# LAN9255ZMX018 register map
Vendor: Microchip
Registers are 32-bit, read-write, reset 0x0 unless marked. A register's access mark holds for its fields unless they carry their own. Addresses are absolute, and some are shared; only a register's first bit layout is shown; [hi:lo] are bit positions; {n}, {i} and the like mark numbered series; 'fields as' and 'values as' point back to an identical list.

## PORT
0x41008000 GROUP0DIR
  [31:0] DIR — Port Data Direction
0x41008004 GROUP0DIRCLR
  [31:0] DIRCLR — Port Data Direction Clear
0x41008008 GROUP0DIRSET
  [31:0] DIRSET — Port Data Direction Set
0x4100800C GROUP0DIRTGL
  [31:0] DIRTGL — Port Data Direction Toggle
0x41008010 GROUP0OUT
  [31:0] OUT — PORT Data Output Value
0x41008014 GROUP0OUTCLR
  [31:0] OUTCLR — PORT Data Output Value Clear
0x41008018 GROUP0OUTSET
  [31:0] OUTSET — PORT Data Output Value Set
0x4100801C GROUP0OUTTGL
  [31:0] OUTTGL — PORT Data Output Value Toggle
0x41008020 GROUP0IN ro
  [31:0] IN — PORT Data Input Value
0x41008024 GROUP0CTRL
  [31:0] SAMPLING — Input Sampling Mode
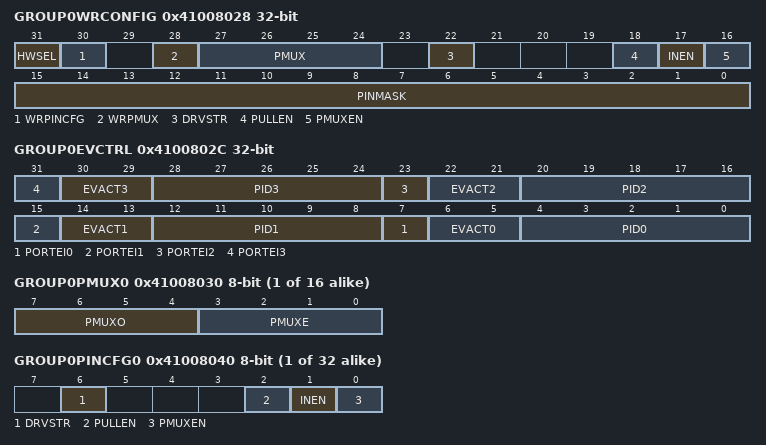
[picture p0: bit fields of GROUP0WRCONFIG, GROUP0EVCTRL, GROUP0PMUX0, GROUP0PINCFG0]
0x41008028 GROUP0WRCONFIG wo
  [31] HWSEL — Half-Word Select
  [30] WRPINCFG — Write PINCFG
  [28] WRPMUX — Write PMUX
  [27:24] PMUX — Peripheral Multiplexing
  [22] DRVSTR — Output Driver Strength Selection
  [18] PULLEN — Pull Enable
  [17] INEN — Input Enable
  [16] PMUXEN — Peripheral Multiplexer Enable
  [15:0] PINMASK — Pin Mask for Multiple Pin Configuration
0x4100802C GROUP0EVCTRL
  [8n+7] PORTEI{n} (n=0..3) — PORT Event Input Enable {n}
  [30:29] EVACT3 — PORT Event Action 3
  [8n+4:8n] PID{n} (n=0..3) — PORT Event Pin Identifier {n}
  [22:21] EVACT2 — PORT Event Action 2
  [14:13] EVACT1 — PORT Event Action 1
  [6:5] EVACT0 — PORT Event Action 0
    0=OUT (Event output to pin); 1=SET (Set output register of pin on event); 2=CLR (Clear output register of pin on event); 3=TGL (Toggle output register of pin on event)
{0x41008030+i} GROUP0PMUX{i} 8-bit (i=0..15)
  [7:4] PMUXO — Peripheral Multiplexing for Odd-Numbered Pin
    0=A (Peripheral function A selected); 1=B (Peripheral function B selected); 2=C (Peripheral function C selected); 3=D (Peripheral function D selected); 4=E (Peripheral function E selected); 5=F (Peripheral function F selected); 6=G (Peripheral function G selected); 7=H (Peripheral function H selected); 8=I (Peripheral function I selected); 9=J (Peripheral function J selected); 10=K (Peripheral function K selected); 11=L (Peripheral function L selected); 12=M (Peripheral function M selected); 13=N (Peripheral function N selected)
  [3:0] PMUXE — Peripheral Multiplexing for Even-Numbered Pin
    values as PMUXO
{0x41008040+i} GROUP0PINCFG{i} 8-bit (i=0..31)
  [6] DRVSTR — Output Driver Strength Selection
  [2] PULLEN — Pull Enable
  [1] INEN — Input Enable
  [0] PMUXEN — Peripheral Multiplexer Enable
0x41008080 GROUP1DIR
  [31:0] DIR — Port Data Direction
0x41008084 GROUP1DIRCLR
  [31:0] DIRCLR — Port Data Direction Clear
0x41008088 GROUP1DIRSET
  [31:0] DIRSET — Port Data Direction Set
0x4100808C GROUP1DIRTGL
  [31:0] DIRTGL — Port Data Direction Toggle
0x41008090 GROUP1OUT
  [31:0] OUT — PORT Data Output Value
0x41008094 GROUP1OUTCLR
  [31:0] OUTCLR — PORT Data Output Value Clear
0x41008098 GROUP1OUTSET
  [31:0] OUTSET — PORT Data Output Value Set
0x4100809C GROUP1OUTTGL
  [31:0] OUTTGL — PORT Data Output Value Toggle
0x410080A0 GROUP1IN ro
  [31:0] IN — PORT Data Input Value
0x410080A4 GROUP1CTRL
  [31:0] SAMPLING — Input Sampling Mode
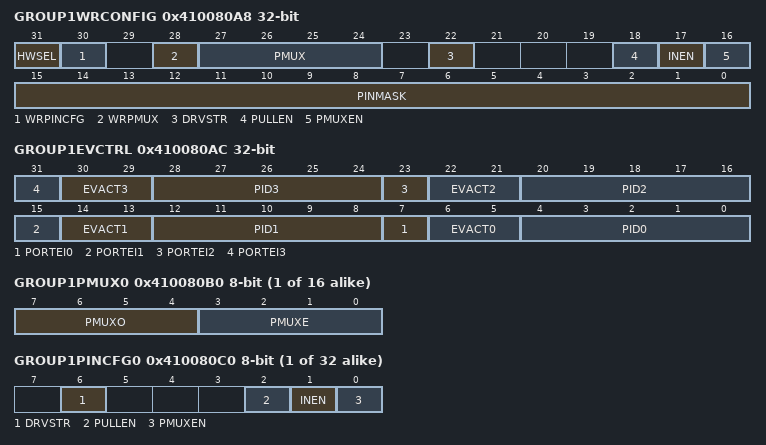
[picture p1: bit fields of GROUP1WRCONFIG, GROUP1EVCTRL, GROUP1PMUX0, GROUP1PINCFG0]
0x410080A8 GROUP1WRCONFIG wo
  fields as GROUP0WRCONFIG
0x410080AC GROUP1EVCTRL
  fields as GROUP0EVCTRL
{0x410080B0+i} GROUP1PMUX{i} 8-bit (i=0..15)
  fields as GROUP0PMUX0
{0x410080C0+i} GROUP1PINCFG{i} 8-bit (i=0..31)
  fields as GROUP0PINCFG0

## HMATRIX
{0x4100C080+8i} PRS{i}PRAS (i=0..15)
{0x4100C084+8i} PRS{i}PRBS (i=0..15)

## EVSYS
0x4100E000 CTRLA 8-bit
  [0] SWRST — Software Reset
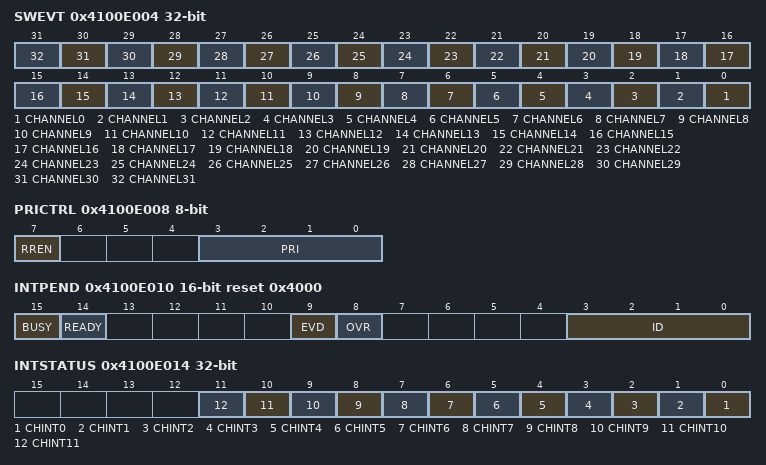
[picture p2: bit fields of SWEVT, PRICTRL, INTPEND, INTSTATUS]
0x4100E004 SWEVT wo
  [n] CHANNEL{n} (n=0..31) — Channel {n} Software Selection
0x4100E008 PRICTRL 8-bit
  [7] RREN — Round-Robin Scheduling Enable
  [3:0] PRI — Channel Priority Number
0x4100E010 INTPEND 16-bit reset 0x4000
  [15] BUSY
  [14] READY
  [9] EVD — Channel Event Detected
  [8] OVR — Channel Overrun
  [3:0] ID — Channel ID
0x4100E014 INTSTATUS ro
  [n] CHINT{n} (n=0..11) — Channel {n} Pending Interrupt
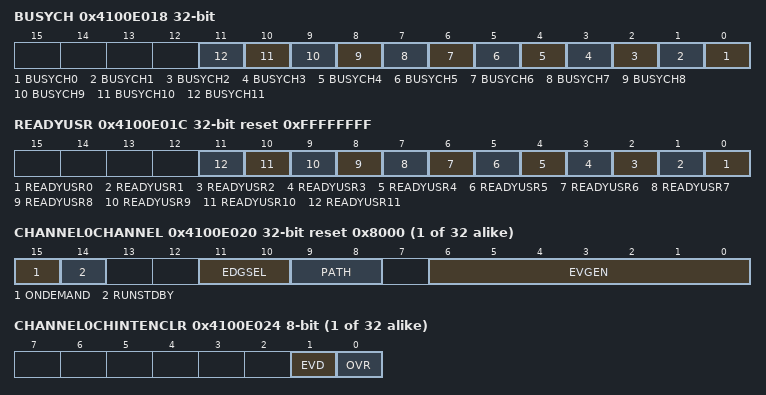
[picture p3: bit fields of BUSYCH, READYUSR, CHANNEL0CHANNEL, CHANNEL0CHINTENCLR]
0x4100E018 BUSYCH ro
  [n] BUSYCH{n} (n=0..11) — Busy Channel {n}
0x4100E01C READYUSR ro reset 0xFFFFFFFF
  [n] READYUSR{n} (n=0..11) — Ready User for Channel {n}
{0x4100E020+8i} CHANNEL{i}CHANNEL reset 0x8000 (i=0..31)
  [15] ONDEMAND — Generic Clock On Demand
  [14] RUNSTDBY — Run in standby
  [11:10] EDGSEL — Edge Detection Selection
    0=NO_EVT_OUTPUT (No event output when using the resynchronized or synchronous path); 1=RISING_EDGE (Event detection only on the rising edge of the signal from the event generator when using the resynchronized or synchronous path); 2=FALLING_EDGE (Event detection only on the falling edge of the signal from the event generator when using the resynchronized or synchronous path); 3=BOTH_EDGES (Event detection on rising and falling edges of the signal from the event generator when using the resynchronized or synchronous path)
  [9:8] PATH — Path Selection
    0=SYNCHRONOUS (Synchronous path); 1=RESYNCHRONIZED (Resynchronized path); 2=ASYNCHRONOUS (Asynchronous path)
  [6:0] EVGEN — Event Generator Selection
{0x4100E024+8i} CHANNEL{i}CHINTENCLR 8-bit (i=0..31)
  [1] EVD — Channel Event Detected Interrupt Disable
  [0] OVR — Channel Overrun Interrupt Disable
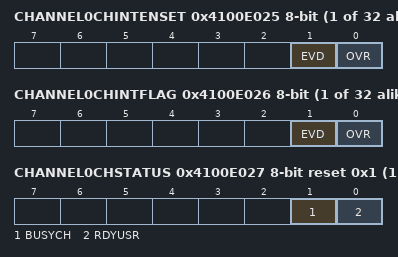
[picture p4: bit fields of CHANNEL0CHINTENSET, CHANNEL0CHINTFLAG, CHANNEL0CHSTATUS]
{0x4100E025+8i} CHANNEL{i}CHINTENSET 8-bit (i=0..31)
  [1] EVD — Channel Event Detected Interrupt Enable
  [0] OVR — Channel Overrun Interrupt Enable
{0x4100E026+8i} CHANNEL{i}CHINTFLAG 8-bit (i=0..31)
  [1] EVD — Channel Event Detected
  [0] OVR — Channel Overrun
{0x4100E027+8i} CHANNEL{i}CHSTATUS 8-bit ro reset 0x1 (i=0..31)
  [1] BUSYCH — Busy Channel
  [0] RDYUSR — Ready User
{0x4100E120+4i} USER{i} (i=0..66)
  [5:0] CHANNEL — Channel Event Selection
